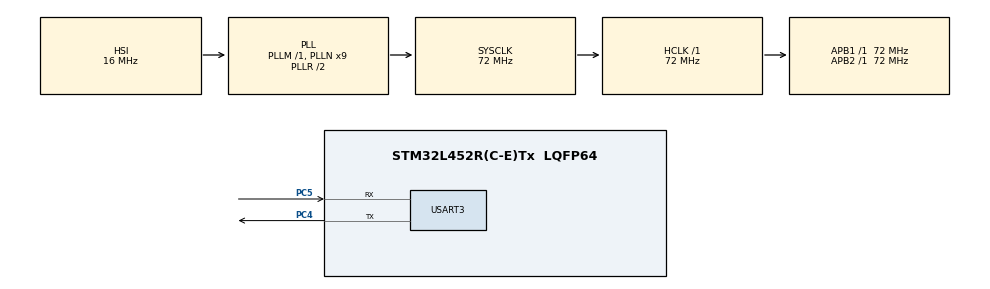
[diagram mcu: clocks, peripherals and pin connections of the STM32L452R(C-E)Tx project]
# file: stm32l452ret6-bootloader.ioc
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Mcu.Family=STM32L4
Mcu.Name=STM32L452R(C-E)Tx
Mcu.Package=LQFP64
NVIC.PriorityGroup=NVIC_PRIORITYGROUP_4
NVIC.TIM1_UP_TIM16_IRQn=true\:15\:0\:false\:false\:true\:false\:true\:true
NVIC.TimeBase=TIM1_UP_TIM16_IRQn
NVIC.TimeBaseIP=TIM1
PA13\ (JTMS/SWDIO).Mode=Trace_Asynchronous_SW
PA13\ (JTMS/SWDIO).Signal=SYS_JTMS-SWDIO
PA14\ (JTCK/SWCLK).Mode=Trace_Asynchronous_SW
PA14\ (JTCK/SWCLK).Signal=SYS_JTCK-SWCLK
PB3\ (JTDO/TRACESWO).Mode=Trace_Asynchronous_SW
PB3\ (JTDO/TRACESWO).Signal=SYS_JTDO-SWO
PC14-OSC32_IN\ (PC14).Mode=LSE-External-Oscillator
PC14-OSC32_IN\ (PC14).Signal=RCC_OSC32_IN
PC15-OSC32_OUT\ (PC15).Mode=LSE-External-Oscillator
PC15-OSC32_OUT\ (PC15).Signal=RCC_OSC32_OUT
PC4.Mode=Asynchronous
PC4.Signal=USART3_TX
PC5.Mode=Asynchronous
PC5.Signal=USART3_RX
PH0-OSC_IN\ (PH0).Mode=HSE-External-Oscillator
PH0-OSC_IN\ (PH0).Signal=RCC_OSC_IN
PH1-OSC_OUT\ (PH1).Mode=HSE-External-Oscillator
PH1-OSC_OUT\ (PH1).Signal=RCC_OSC_OUT
ProjectManager.HeapSize=0x200
ProjectManager.StackSize=0x400
ProjectManager.TargetToolchain=Makefile
RCC.ADCFreq_Value=64000000
RCC.AHBFreq_Value=72000000
RCC.APB1Freq_Value=72000000
RCC.APB1TimFreq_Value=72000000
RCC.APB2Freq_Value=72000000
RCC.APB2TimFreq_Value=72000000
RCC.CortexFreq_Value=72000000
RCC.HCLKFreq_Value=72000000
RCC.HSE_VALUE=8000000
RCC.HSI48_VALUE=48000000
RCC.HSI_VALUE=16000000
RCC.MSI_VALUE=4000000
RCC.PLLN=9
RCC.PLLSourceVirtual=RCC_PLLSOURCE_HSI
RCC.SYSCLKFreq_VALUE=72000000
RCC.SYSCLKSource=RCC_SYSCLKSOURCE_PLLCLK
RCC.USBFreq_Value=64000000
RCC.VCOOutputFreq_Value=144000000
USART3.VirtualMode-Asynchronous=VM_ASYNC
VP_CRC_VS_CRC.Mode=CRC_Activate
VP_SYS_VS_tim1.Mode=TIM1
board=custom

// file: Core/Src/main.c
/* USER CODE BEGIN Header */
/**
  ******************************************************************************
  * @file           : main.c
  * @brief          : Main program body
  ******************************************************************************
  * @attention
  *
  * Copyright (c) 2024 STMicroelectronics.
  * All rights reserved.
  *
  * This software is licensed under terms that can be found in the LICENSE file
  * in the root directory of this software component.
  * If no LICENSE file comes with this software, it is provided AS-IS.
  *
  ******************************************************************************
  */
/* USER CODE END Header */
#include "main.h"

/* USER CODE BEGIN Includes */
#include "stm32_bootloader.h"
/* USER CODE END Includes */

CRC_HandleTypeDef hcrc;

UART_HandleTypeDef huart3;

void SystemClock_Config(void);
static void MX_GPIO_Init(void);
static void MX_CRC_Init(void);
static void MX_USART3_UART_Init(void);

int main(void)
{

  /* MCU Configuration--------------------------------------------------------*/

  /* Reset of all peripherals, Initializes the Flash interface and the Systick. */
  HAL_Init();

  /* Configure the system clock */
  SystemClock_Config();

  /* Initialize all configured peripherals */
  MX_GPIO_Init();
  MX_CRC_Init();
  MX_USART3_UART_Init();
  /* USER CODE BEGIN 2 */
  STM32_Bootloader_Init();
  STM32_Bootloader_Process();
  /* USER CODE END 2 */

  /* Infinite loop */
  while (1)
  {

  }
}

void SystemClock_Config(void)
{
  RCC_OscInitTypeDef RCC_OscInitStruct = {0};
  RCC_ClkInitTypeDef RCC_ClkInitStruct = {0};

  /** Configure the main internal regulator output voltage
  */
  if (HAL_PWREx_ControlVoltageScaling(PWR_REGULATOR_VOLTAGE_SCALE1) != HAL_OK)
  {
    Error_Handler();
  }

  /** Initializes the RCC Oscillators according to the specified parameters
  * in the RCC_OscInitTypeDef structure.
  */
  RCC_OscInitStruct.OscillatorType = RCC_OSCILLATORTYPE_HSI;
  RCC_OscInitStruct.HSIState = RCC_HSI_ON;
  RCC_OscInitStruct.HSICalibrationValue = 64;
  RCC_OscInitStruct.PLL.PLLState = RCC_PLL_ON;
  RCC_OscInitStruct.PLL.PLLSource = RCC_PLLSOURCE_HSI;
  RCC_OscInitStruct.PLL.PLLM = 1;
  RCC_OscInitStruct.PLL.PLLN = 9;
  RCC_OscInitStruct.PLL.PLLP = RCC_PLLP_DIV7;
  RCC_OscInitStruct.PLL.PLLQ = RCC_PLLQ_DIV2;
  RCC_OscInitStruct.PLL.PLLR = RCC_PLLR_DIV2;
  if (HAL_RCC_OscConfig(&RCC_OscInitStruct) != HAL_OK)
  {
    Error_Handler();
  }

  /** Initializes the CPU, AHB and APB buses clocks
  */
  RCC_ClkInitStruct.ClockType = RCC_CLOCKTYPE_HCLK|RCC_CLOCKTYPE_SYSCLK
                              |RCC_CLOCKTYPE_PCLK1|RCC_CLOCKTYPE_PCLK2;
  RCC_ClkInitStruct.SYSCLKSource = RCC_SYSCLKSOURCE_PLLCLK;
  RCC_ClkInitStruct.AHBCLKDivider = RCC_SYSCLK_DIV1;
  RCC_ClkInitStruct.APB1CLKDivider = RCC_HCLK_DIV1;
  RCC_ClkInitStruct.APB2CLKDivider = RCC_HCLK_DIV1;

  if (HAL_RCC_ClockConfig(&RCC_ClkInitStruct, FLASH_LATENCY_4) != HAL_OK)
  {
    Error_Handler();
  }
}

static void MX_CRC_Init(void)
{

  hcrc.Instance = CRC;
  hcrc.Init.DefaultPolynomialUse = DEFAULT_POLYNOMIAL_ENABLE;
  hcrc.Init.DefaultInitValueUse = DEFAULT_INIT_VALUE_ENABLE;
  hcrc.Init.InputDataInversionMode = CRC_INPUTDATA_INVERSION_NONE;
  hcrc.Init.OutputDataInversionMode = CRC_OUTPUTDATA_INVERSION_DISABLE;
  hcrc.InputDataFormat = CRC_INPUTDATA_FORMAT_BYTES;
  if (HAL_CRC_Init(&hcrc) != HAL_OK)
  {
    Error_Handler();
  }

}

static void MX_USART3_UART_Init(void)
{

  huart3.Instance = USART3;
  huart3.Init.BaudRate = 115200;
  huart3.Init.WordLength = UART_WORDLENGTH_8B;
  huart3.Init.StopBits = UART_STOPBITS_1;
  huart3.Init.Parity = UART_PARITY_NONE;
  huart3.Init.Mode = UART_MODE_TX_RX;
  huart3.Init.HwFlowCtl = UART_HWCONTROL_NONE;
  huart3.Init.OverSampling = UART_OVERSAMPLING_16;
  huart3.Init.OneBitSampling = UART_ONE_BIT_SAMPLE_DISABLE;
  huart3.AdvancedInit.AdvFeatureInit = UART_ADVFEATURE_NO_INIT;
  if (HAL_UART_Init(&huart3) != HAL_OK)
  {
    Error_Handler();
  }

}

static void MX_GPIO_Init(void)
{

  /* GPIO Ports Clock Enable */
  __HAL_RCC_GPIOC_CLK_ENABLE();
  __HAL_RCC_GPIOH_CLK_ENABLE();
  __HAL_RCC_GPIOA_CLK_ENABLE();
  __HAL_RCC_GPIOB_CLK_ENABLE();

}

void HAL_TIM_PeriodElapsedCallback(TIM_HandleTypeDef *htim)
{
  if (htim->Instance == TIM1) {
    HAL_IncTick();
  }
}

void Error_Handler(void)
{
  __disable_irq();
  while (1)
  {
  }
}
